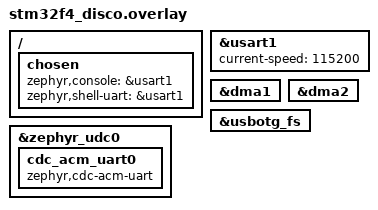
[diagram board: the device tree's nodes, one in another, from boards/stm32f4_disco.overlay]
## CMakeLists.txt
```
# SPDX-License-Identifier: Apache-2.0

cmake_minimum_required(VERSION 3.20.0)

find_package(Zephyr REQUIRED HINTS $ENV{ZEPHYR_BASE})
project(hello_world)

target_sources(app PRIVATE 
    src/main.c
    src/fault.c
)
```

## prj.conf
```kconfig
CONFIG_LOG=y
CONFIG_LOG_CMDS=y
CONFIG_SHELL_BACKEND_SERIAL_LOG_MESSAGE_QUEUE_SIZE=4096

CONFIG_SHELL=y
CONFIG_SHELL_STACK_SIZE=1024
CONFIG_LOG_MODE_IMMEDIATE=y

CONFIG_DEBUG_COREDUMP=y
CONFIG_DEBUG_COREDUMP_BACKEND_LOGGING=y
CONFIG_DEBUG_COREDUMP_MEMORY_DUMP_MIN=y
```

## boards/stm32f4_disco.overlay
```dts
/ {
	chosen {
		zephyr,console = &usart1;
		zephyr,shell-uart = &usart1;
	};
};

&usart1 {
	current-speed = <115200>;
};

&dma1 {
	status = "okay";
};

&dma2 {
	status = "okay";
};

zephyr_uhc0: &usbotg_fs {
	status = "okay";
};

&zephyr_udc0 {
	cdc_acm_uart0: cdc_acm_uart0 {
		compatible = "zephyr,cdc-acm-uart";
	};
};
```

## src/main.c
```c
/*
 * Copyright (c) 2012-2014 Wind River Systems, Inc.
 *
 * SPDX-License-Identifier: Apache-2.0
 */

#include <stdio.h>
#include <zephyr/kernel.h>
#include <zephyr/kernel.h>
#include <zephyr/sys/printk.h>
#include <zephyr/drivers/uart.h>

#include <zephyr/logging/log.h>
LOG_MODULE_REGISTER(main, LOG_LEVEL_DBG);

#define BRUCE_STACK_SIZE 1024
K_THREAD_STACK_DEFINE(bruce_stack, BRUCE_STACK_SIZE);
struct k_thread bruce_thread_data = {0};

int sum(int a, int b)
{
	int c = a + b;

	return c;
}

void thread_bruce_entry()
{
	int s1 = sum(2, 3);
	int s2 = -1;

	while(1)
	{
		k_sleep(K_SECONDS(2));
		LOG_WRN("sum : %d\r\n", sum(6, 7));
		LOG_DBG("size : %d", bruce_thread_data.stack_info.size);
	}
}
int main(void)
{
	printf("Hello World! %s\n", CONFIG_BOARD);

	k_thread_create(&bruce_thread_data,
		bruce_stack,
		K_THREAD_STACK_SIZEOF(bruce_stack),
		thread_bruce_entry,
		NULL, NULL, NULL,
		5, 0, K_NO_WAIT);
	
	return 0;
}
```

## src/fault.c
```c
#include <stdio.h>
#include <zephyr/kernel.h>
#include <zephyr/shell/shell.h>

#include <zephyr/logging/log.h>
LOG_MODULE_REGISTER(fault, LOG_LEVEL_DBG);

int _example_fault_t1(const struct shell *sh, size_t argc, char *argv[])
{
    int a = 1; 
	int b = 0;
    int c = a / b;

    LOG_DBG("c = %d", c);
    
	return 0;
}

int _example_fault_t2(const struct shell *sh, size_t argc, char *argv[])
{
    struct student {
        uint8_t age;
        char name[64];
    };

    struct student *stu = NULL;

    LOG_DBG("age = %d", stu->age);
    LOG_DBG("name = %s", stu->name);
    
	return 0;
}

int _example_fault_t3(const struct shell *sh, size_t argc, char *argv[])
{
    LOG_DBG("%s", CONFIG_KERNEL_ENTRY);

    extern char __bss_start[];
    extern char __bss_end[];
    LOG_DBG("%p", __bss_start);
    LOG_DBG("%p", __bss_end);
    
	return 0;
}

SHELL_STATIC_SUBCMD_SET_CREATE(fault_commands,
	SHELL_CMD(t1, NULL,
		"usage fault t1",
		_example_fault_t1),
    SHELL_CMD(t2, NULL,
		"usage fault t2",
		_example_fault_t2),
    SHELL_CMD(t3, NULL,
		"usage fault t3",
		_example_fault_t3),
	SHELL_SUBCMD_SET_END
);

SHELL_CMD_REGISTER(fault, &fault_commands,
		   "example for fault", NULL);
```
